VERSION ""

NS_ :

BS_ :

BU_: VCU MCU BJM1 BJM2 BJM3

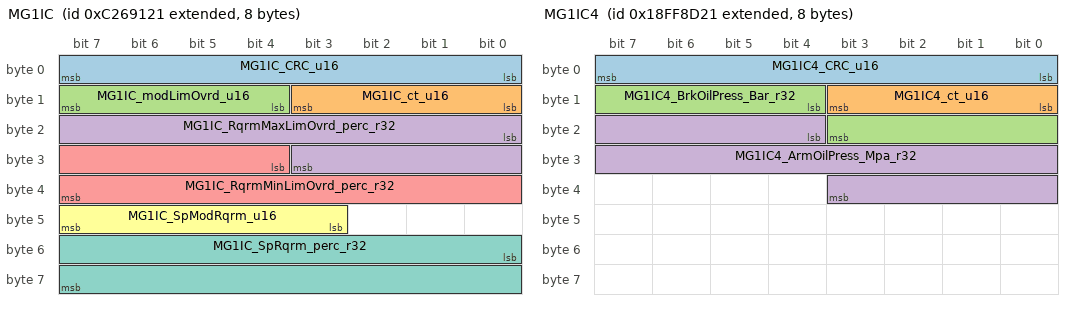
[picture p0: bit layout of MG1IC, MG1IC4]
BO_ 2351337761 MG1IC: 8 Vector__XXX
 SG_ MG1IC_CRC_u16 : 0|8@1- (1,0) [0|255] "count" MCU
 SG_ MG1IC_ct_u16 : 8|4@1- (1,0) [0|15] "" MCU
 SG_ MG1IC_modLimOvrd_u16 : 12|4@1- (1,0) [0|15] "" MCU
 SG_ MG1IC_RqrmMaxLimOvrd_perc_r32 : 16|12@1- (0.0625,-125) [-125|125.9375] "%" MCU
 SG_ MG1IC_RqrmMinLimOvrd_perc_r32 : 28|12@1- (0.0625,-125) [-125|125.9375] "%" MCU
 SG_ MG1IC_SpModRqrm_u16 : 43|5@1- (1,0) [0|31] "" MCU
 SG_ MG1IC_SpRqrm_perc_r32 : 48|16@1- (0.00390625,-125) [-125|125.99609375] "%" MCU

BO_ 2566884641 MG1IC4: 8 Vector__XXX
 SG_ MG1IC4_CRC_u16 : 0|8@1- (1,0) [0|255] "count" MCU
 SG_ MG1IC4_ct_u16 : 8|4@1- (1,0) [0|15] "" MCU
 SG_ MG1IC4_BrkOilPress_Bar_r32 : 12|8@1- (0.5,0) [0|125] "bar" MCU
 SG_ MG1IC4_ArmOilPress_Mpa_r32 : 20|16@1- (0.0009765625,0) [0|62.7490234375] "Mpa" MCU

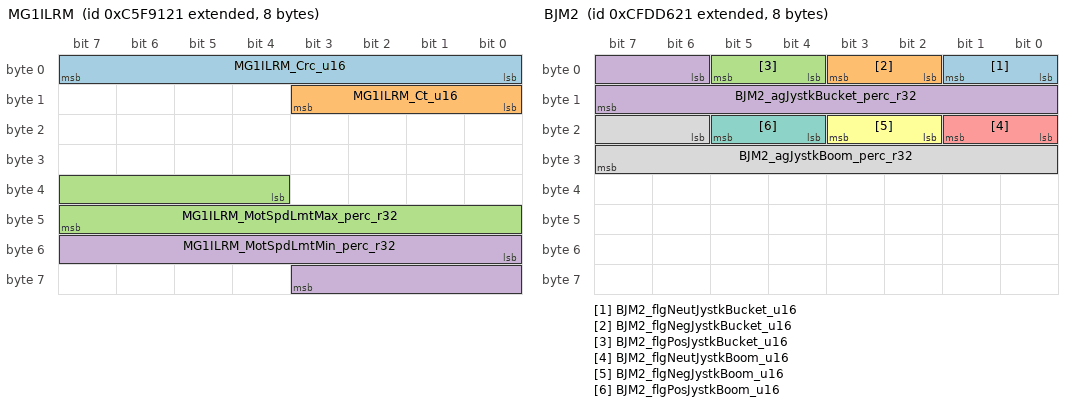
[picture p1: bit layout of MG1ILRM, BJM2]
BO_ 2355073313 MG1ILRM: 8 Vector__XXX
 SG_ MG1ILRM_Crc_u16 : 0|8@1- (1,0) [0|255] "count" MCU
 SG_ MG1ILRM_Ct_u16 : 8|4@1- (1,0) [0|15] "" MCU
 SG_ MG1ILRM_MotSpdLmtMax_perc_r32 : 36|12@1- (0,0) [-125|0] "%" MCU
 SG_ MG1ILRM_MotSpdLmtMin_perc_r32 : 48|12@1- (0,0) [-125|0] "%" MCU

BO_ 2365445665 BJM2: 8 Vector__XXX
 SG_ BJM2_flgNeutJystkBucket_u16 : 0|2@1- (1,0) [0|3] "" MCU
 SG_ BJM2_flgNegJystkBucket_u16 : 2|2@1- (1,0) [0|3] "" MCU
 SG_ BJM2_flgPosJystkBucket_u16 : 4|2@1- (1,0) [0|3] "" MCU
 SG_ BJM2_agJystkBucket_perc_r32 : 6|10@1- (0.1,0) [0|102] "%" MCU
 SG_ BJM2_flgNeutJystkBoom_u16 : 16|2@1- (1,0) [0|3] "" MCU
 SG_ BJM2_flgNegJystkBoom_u16 : 18|2@1- (1,0) [0|3] "" MCU
 SG_ BJM2_flgPosJystkBoom_u16 : 20|2@1- (1,0) [0|3] "" MCU
 SG_ BJM2_agJystkBoom_perc_r32 : 22|10@1- (0.1,0) [0|102] "%" MCU

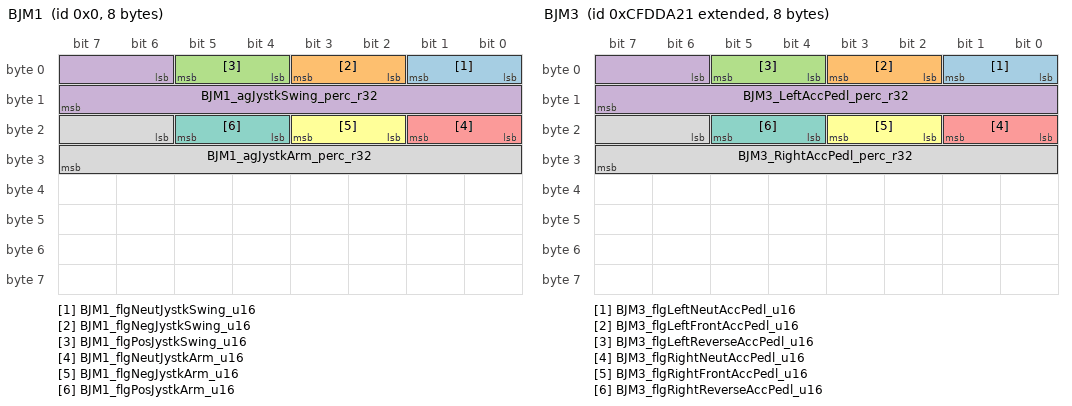
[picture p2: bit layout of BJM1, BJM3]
BO_ 0 BJM1: 8 Vector__XXX
 SG_ BJM1_flgNeutJystkSwing_u16 : 0|2@1- (1,0) [0|3] "" MCU
 SG_ BJM1_flgNegJystkSwing_u16 : 2|2@1- (1,0) [0|3] "" MCU
 SG_ BJM1_flgPosJystkSwing_u16 : 4|2@1- (1,0) [0|3] "" MCU
 SG_ BJM1_agJystkSwing_perc_r32 : 6|10@1- (0.1,0) [0|102] "%" MCU
 SG_ BJM1_flgNeutJystkArm_u16 : 16|2@1- (1,0) [0|3] "" MCU
 SG_ BJM1_flgNegJystkArm_u16 : 18|2@1- (1,0) [0|3] "" MCU
 SG_ BJM1_flgPosJystkArm_u16 : 20|2@1- (1,0) [0|3] "" MCU
 SG_ BJM1_agJystkArm_perc_r32 : 22|10@1- (0.1,0) [0|102] "%" MCU

BO_ 2365446689 BJM3: 8 Vector__XXX
 SG_ BJM3_flgLeftNeutAccPedl_u16 : 0|2@1- (1,0) [0|3] "" MCU
 SG_ BJM3_flgLeftFrontAccPedl_u16 : 2|2@1- (1,0) [0|3] "" MCU
 SG_ BJM3_flgLeftReverseAccPedl_u16 : 4|2@1- (1,0) [0|3] "" MCU
 SG_ BJM3_LeftAccPedl_perc_r32 : 6|10@1- (0.1,0) [0|102] "%" MCU
 SG_ BJM3_flgRightNeutAccPedl_u16 : 16|2@1- (1,0) [0|3] "" MCU
 SG_ BJM3_flgRightFrontAccPedl_u16 : 18|2@1- (1,0) [0|3] "" MCU
 SG_ BJM3_flgRightReverseAccPedl_u16 : 20|2@1- (1,0) [0|3] "" MCU
 SG_ BJM3_RightAccPedl_perc_r32 : 22|10@1- (0.1,0) [0|102] "%" MCU

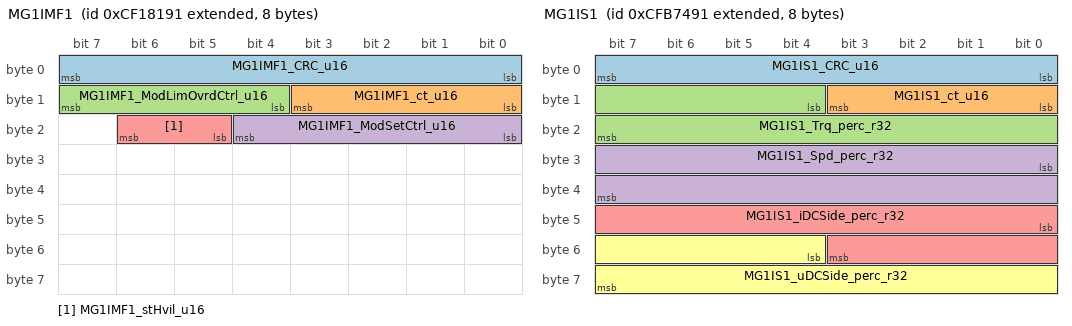
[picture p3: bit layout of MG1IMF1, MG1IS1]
BO_ 2364637585 MG1IMF1: 8 Vector__XXX
 SG_ MG1IMF1_CRC_u16 : 0|8@1- (1,0) [0|255] "count" VCU
 SG_ MG1IMF1_ct_u16 : 8|4@1- (1,0) [0|15] "" VCU
 SG_ MG1IMF1_ModLimOvrdCtrl_u16 : 12|4@1- (1,0) [0|15] "" VCU
 SG_ MG1IMF1_ModSetCtrl_u16 : 16|5@1- (1,0) [0|31] "" VCU
 SG_ MG1IMF1_stHvil_u16 : 21|2@1- (1,0) [0|3] "" VCU

BO_ 2365289617 MG1IS1: 8 Vector__XXX
 SG_ MG1IS1_CRC_u16 : 0|8@1- (1,0) [0|255] "count" VCU
 SG_ MG1IS1_ct_u16 : 8|4@1- (1,0) [0|15] "" VCU
 SG_ MG1IS1_Trq_perc_r32 : 12|12@1- (0.0625,-125) [-125|125.9375] "%" VCU
 SG_ MG1IS1_Spd_perc_r32 : 24|16@1- (0.00390625,-125) [-125|125.99609375] "%" VCU
 SG_ MG1IS1_iDCSide_perc_r32 : 40|12@1- (0.0625,-125) [-125|125.9375] "%" VCU
 SG_ MG1IS1_uDCSide_perc_r32 : 52|12@1- (0.0625,-125) [-125|125.9375] "%" VCU

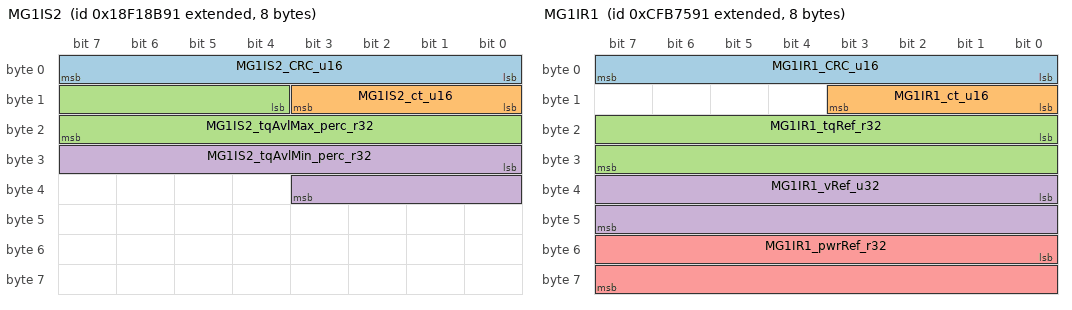
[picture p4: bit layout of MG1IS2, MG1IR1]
BO_ 2565966737 MG1IS2: 8 Vector__XXX
 SG_ MG1IS2_CRC_u16 : 0|8@1- (1,0) [0|255] "" VCU
 SG_ MG1IS2_ct_u16 : 8|4@1- (1,0) [0|15] "" VCU
 SG_ MG1IS2_tqAvlMax_perc_r32 : 12|12@1- (0.0625,-125) [-125|125.9375] "%" VCU
 SG_ MG1IS2_tqAvlMin_perc_r32 : 24|12@1- (0.0625,-125) [-125|125.9375] "%" VCU

BO_ 2365289873 MG1IR1: 8 Vector__XXX
 SG_ MG1IR1_CRC_u16 : 0|8@1- (1,0) [0|255] "count" VCU
 SG_ MG1IR1_ct_u16 : 8|4@1- (1,0) [0|15] "" VCU
 SG_ MG1IR1_tqRef_r32 : 16|16@1- (0.5,0) [0|32127.5] "Nm" VCU
 SG_ MG1IR1_vRef_u32 : 32|16@1- (4,0) [0|257020] "rpm" VCU
 SG_ MG1IR1_pwrRef_r32 : 48|16@1- (0.0625,0) [0|4015.9375] "kW" VCU

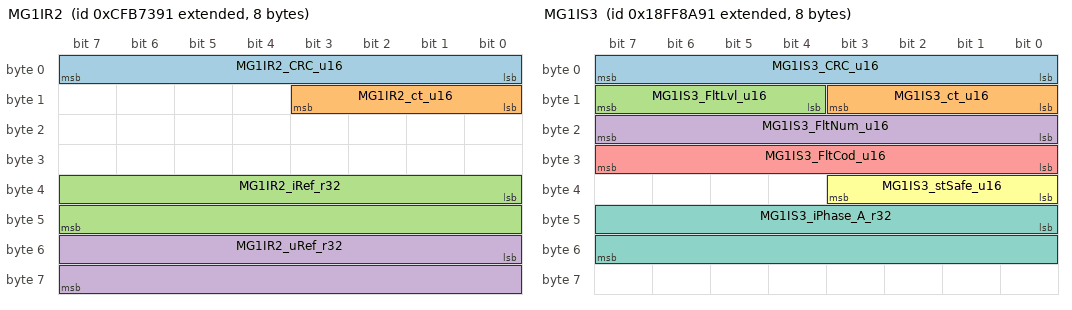
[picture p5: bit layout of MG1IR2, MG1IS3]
BO_ 2365289361 MG1IR2: 8 Vector__XXX
 SG_ MG1IR2_CRC_u16 : 0|8@1- (1,0) [0|255] "count" VCU
 SG_ MG1IR2_ct_u16 : 8|4@1- (1,0) [0|15] "" VCU
 SG_ MG1IR2_iRef_r32 : 32|16@1- (0.125,0) [0|8031.875] "A" VCU
 SG_ MG1IR2_uRef_r32 : 48|16@1- (0.125,0) [0|8031.875] "V" VCU

BO_ 2566615441 MG1IMT: 8 Vector__XXX
 SG_ MG1IMT_t1Mot_u16 : 0|8@1- (1,-40) [-40|210] "°C" VCU

BO_ 2566615697 MG1IT: 8 Vector__XXX
 SG_ MG1IT_t1Ivtr_u16 : 0|8@1- (1,-40) [-40|210] "°C" VCU

BO_ 2566883985 MG1IS3: 8 Vector__XXX
 SG_ MG1IS3_CRC_u16 : 0|8@1- (1,0) [0|255] "count" VCU
 SG_ MG1IS3_ct_u16 : 8|4@1- (1,0) [0|15] "" VCU
 SG_ MG1IS3_FltLvl_u16 : 12|4@1- (1,0) [0|15] "" VCU
 SG_ MG1IS3_FltNum_u16 : 16|8@1- (1,0) [0|255] "count" VCU
 SG_ MG1IS3_FltCod_u16 : 24|8@1- (1,0) [0|255] "" VCU
 SG_ MG1IS3_stSafe_u16 : 32|4@1- (1,0) [0|15] "" VCU
 SG_ MG1IS3_iPhase_A_r32 : 40|16@1- (0.1,0) [-3212.7|3212.8] "A" VCU

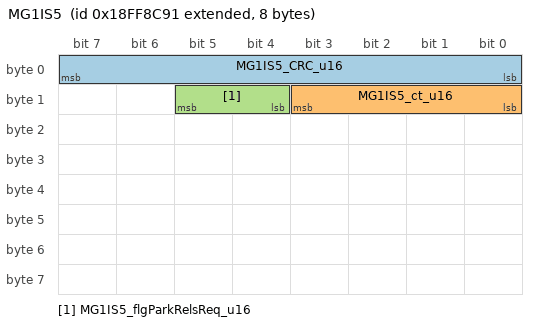
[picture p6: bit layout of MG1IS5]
BO_ 2566884497 MG1IS5: 8 Vector__XXX
 SG_ MG1IS5_CRC_u16 : 0|8@1- (1,0) [0|255] "count" VCU
 SG_ MG1IS5_ct_u16 : 8|4@1- (1,0) [0|15] "" VCU
 SG_ MG1IS5_flgParkRelsReq_u16 : 12|2@1- (1,0) [0|3] "" VCU

CM_ BO_ 2351337761 "Motor/Generator 1 Inverter Control";
CM_ SG_ 2351337761 MG1IC_CRC_u16 "CRC";
CM_ SG_ 2351337761 MG1IC_ct_u16 "Counter";
CM_ SG_ 2351337761 MG1IC_modLimOvrd_u16 "This parameter provides a way to temporarily override limits that are being received by the inverter in other messages.  It allows a specific type of limit to be transmitted at a high rate or at the same moment as the set point for synchronization purposes.
过载限制模式";
CM_ SG_ 2351337761 MG1IC_RqrmMaxLimOvrd_perc_r32 "The Maximum limit requested by this parameter depends on the value of SPN 10159 [Control Limits Request Override Mode].
过载限制模式最大百分比";
CM_ SG_ 2351337761 MG1IC_RqrmMinLimOvrd_perc_r32 "The Minimum limit requested by this parameter depends on the value of SPN 10159 [Control Limits Request Override Mode].
过载限制模式最小百分比";
CM_ SG_ 2351337761 MG1IC_SpModRqrm_u16 "Requests the modes for this instance of the inverter.  See SPN 10167 [Control Setpoint Mode] for the feedback to this request.
工作模式设置";
CM_ SG_ 2351337761 MG1IC_SpRqrm_perc_r32 "Requests the set point for this inverter.  The type of set point requested by this parameter depends on the value of SPN 10162 [Control Setpoint Mode Request] as follows:
对应工作模式的需求百分比";
CM_ BO_ 2566884641 "Motor/Generator 1 Inverter Control 4";
CM_ SG_ 2566884641 MG1IC4_CRC_u16 "CRC";
CM_ SG_ 2566884641 MG1IC4_ct_u16 "Counter";
CM_ SG_ 2566884641 MG1IC4_BrkOilPress_Bar_r32 "Brake oil pressure
松闸油压信号";
CM_ SG_ 2566884641 MG1IC4_ArmOilPress_Mpa_r32 "Boom cylinder rod pressure
动臂小腔油压";
CM_ BO_ 2355073313 "Motor/Generator 1 Inverter Limits Request Mechanical";
CM_ SG_ 2355073313 MG1ILRM_MotSpdLmtMax_perc_r32 "This is a request to the inverter to set a maximum speed limit for this device.
电机最高转速限制";
CM_ SG_ 2355073313 MG1ILRM_MotSpdLmtMin_perc_r32 "This is a request to the inverter to set a minimum speed limit for this device.
电机最低转速限制";
CM_ BO_ 2365445665 "Basic Joystick Message2";
CM_ SG_ 2365445665 BJM2_flgNeutJystkBucket_u16 "Bucket joystick median signal
铲斗手柄中位信号";
CM_ SG_ 2365445665 BJM2_flgNegJystkBucket_u16 "Bucket joystick negative signal
铲斗手柄负位信号";
CM_ SG_ 2365445665 BJM2_flgPosJystkBucket_u16 "Bucket joystick positive signal
铲斗手柄正位信号";
CM_ SG_ 2365445665 BJM2_agJystkBucket_perc_r32 "Bucket joystick joystick signal
铲斗手柄信号";
CM_ SG_ 2365445665 BJM2_flgNeutJystkBoom_u16 "Boom joystick median signal
动臂手柄中位信号";
CM_ SG_ 2365445665 BJM2_flgNegJystkBoom_u16 "Boom joystick negative signal
动臂手柄负位信号";
CM_ SG_ 2365445665 BJM2_flgPosJystkBoom_u16 "Boom joystick positive signal
动臂手柄正位信号";
CM_ SG_ 2365445665 BJM2_agJystkBoom_perc_r32 "Boom joystick signal
动臂手柄信号";
CM_ BO_ 0 "Basic Joystick Message 1";
CM_ SG_ 0 BJM1_flgNeutJystkSwing_u16 "Swing joystick median signal
回转手柄中位信号";
CM_ SG_ 0 BJM1_flgNegJystkSwing_u16 "Swing joystick negative signal
回转手柄负位信号";
CM_ SG_ 0 BJM1_flgPosJystkSwing_u16 "Swing joystick positive signal
回转手柄正位信号";
CM_ SG_ 0 BJM1_agJystkSwing_perc_r32 "Swing joystick joystick signal
回转手柄信号";
CM_ SG_ 0 BJM1_flgNeutJystkArm_u16 "Arm joystick median signal
斗杆手柄中位信号";
CM_ SG_ 0 BJM1_flgNegJystkArm_u16 "Arm lever joystick negative signal
斗杆手柄负位信号";
CM_ SG_ 0 BJM1_flgPosJystkArm_u16 "Arm lever joystick positive signal
斗杆手柄正位信号";
CM_ SG_ 0 BJM1_agJystkArm_perc_r32 "Arm  lever joystick signal
斗杆手柄信号";
CM_ BO_ 2365446689 "Basic Joystick Message3";
CM_ SG_ 2365446689 BJM3_flgLeftNeutAccPedl_u16 "Left accelerator pedal median signal
左行走踏板中位信号";
CM_ SG_ 2365446689 BJM3_flgLeftFrontAccPedl_u16 "Left accelerator pedal front signal
左行走踏板正位信号";
CM_ SG_ 2365446689 BJM3_flgLeftReverseAccPedl_u16 "Left accelerator pedal reverse signal
左行走踏板负位信号";
CM_ SG_ 2365446689 BJM3_LeftAccPedl_perc_r32 "Left accelerator pedal signal
左行走踏板信号";
CM_ SG_ 2365446689 BJM3_flgRightNeutAccPedl_u16 "Right accelerator pedal median signal
右行走踏板中位信号";
CM_ SG_ 2365446689 BJM3_flgRightFrontAccPedl_u16 "Right accelerator pedal front signal
右行走踏板正位信号";
CM_ SG_ 2365446689 BJM3_flgRightReverseAccPedl_u16 "Right accelerator pedal reverse signal
右行走踏板负位信号";
CM_ SG_ 2365446689 BJM3_RightAccPedl_perc_r32 "Right accelerator pedal signal
右行走踏板信号";
CM_ BO_ 2364637585 "Motor/Generator 1 Inverter Mode Feedback 1";
CM_ SG_ 2364637585 MG1IMF1_CRC_u16 "CRC";
CM_ SG_ 2364637585 MG1IMF1_ct_u16 "Counter";
CM_ SG_ 2364637585 MG1IMF1_ModLimOvrdCtrl_u16 "Inverter Control Limits Override Mode
当前的过载限制模式";
CM_ SG_ 2364637585 MG1IMF1_ModSetCtrl_u16 "Inverter Control Setpoint Mode
当前的工作模式";
CM_ SG_ 2364637585 MG1IMF1_stHvil_u16 "Inverter HVIL Status
当前的高压互锁状态";
CM_ BO_ 2365289617 "Motor/Generator 1 Inverter Status 1";
CM_ SG_ 2365289617 MG1IS1_CRC_u16 "CRC";
CM_ SG_ 2365289617 MG1IS1_ct_u16 "Counter";
CM_ SG_ 2365289617 MG1IS1_Trq_perc_r32 "The calculated Torque
当前的扭矩百分比";
CM_ SG_ 2365289617 MG1IS1_Spd_perc_r32 "The measured Speed
当前的速度百分比";
CM_ SG_ 2365289617 MG1IS1_iDCSide_perc_r32 "This is the DC side current of the inverter. Refer to SPN 10202 [Reference Current] to convert % to Amps. While motoring, the current is defined as positive.  For example, in a hybrid propulsion system, positive current flows from the HVES through ...This is the DC side current of the inverter. Refer to SPN 10202 [Reference Current] to convert % to Amps. While motoring, the current is defined as positive.  For example, in a hybrid propulsion system, positive current flows from the HVES through ...
当前的DC端电流百分比";
CM_ SG_ 2365289617 MG1IS1_uDCSide_perc_r32 "The measured or estimated DC side voltage. Refer to SPN 10203 [Reference Voltage] to convert % to Volts.
当前的DC端电压百分比";
CM_ BO_ 2565966737 "Motor/Generator 1 Inverter Status 2";
CM_ SG_ 2565966737 MG1IS2_CRC_u16 "CRC";
CM_ SG_ 2565966737 MG1IS2_ct_u16 "Counter";
CM_ SG_ 2565966737 MG1IS2_tqAvlMax_perc_r32 "This is an estimate of the maximum available motor torque including active deratings at the present motor speed.  This refers to the motor rotor output and excludes any gearbox that may be attached to the motor.   
当前的最大可用扭矩百分比";
CM_ SG_ 2565966737 MG1IS2_tqAvlMin_perc_r32 "This is an estimate of the minimum available motor torque including active deratings at the present motor speed.  This refers to the motor rotor output and excludes any gearbox that may be attached to the motor.  
当前的最小可用扭矩百分比";
CM_ BO_ 2365289873 "Motor/Generator 1 Inverter Reference 1";
CM_ SG_ 2365289873 MG1IR1_CRC_u16 "CRC";
CM_ SG_ 2365289873 MG1IR1_ct_u16 "Counter";
CM_ SG_ 2365289873 MG1IR1_tqRef_r32 "This value is used for converting torque in percent to units of Nm.

Value in Nm = (Percent Value)/(100%) * (Reference Torque)

For example, if this parameter has a value of 400 Nm and the percent value is equal to 75%, then the value in Nm will be found as follows:

Value in Nm = (75%)/(100%) * (400 Nm) = 300 Nm
参照扭矩，用于配合百分比值进行计算";
CM_ SG_ 2365289873 MG1IR1_vRef_u32 "This value is used for converting Speed in percent to units of rpm.

Value in rpm = (Percent Value)/(100%) * (Reference Speed)

For example, if this parameter has a value of 8192 rpm and the percent value is equal to 75%, then the value in rpm will be found as follows:

Value in rpm = (75%)/(100%) * (8192 rpm) = 6144 rpm
参照转速，用于配合百分比值进行计算";
CM_ SG_ 2365289873 MG1IR1_pwrRef_r32 "This value is used for converting power in percent to units of kW.  It is applicable to both mechanical and electrical power.

(Value in kW) = (Percent Value)/(100%) * (Reference Power)

For example, if this parameter has a value of 400 kW and the percent value is equal to 75%, then the value in kW will be found as follows:

Value in kW = (75%)/(100%) * (400 kW) = 300 kW
参照功率，用于配合百分比值进行计算";
CM_ BO_ 2365289361 "Motor/Generator 1 Inverter Reference 2";
CM_ SG_ 2365289361 MG1IR2_CRC_u16 "CRC";
CM_ SG_ 2365289361 MG1IR2_ct_u16 "Counter";
CM_ SG_ 2365289361 MG1IR2_iRef_r32 "This value is used for converting inverter current in percent to units of Amps (RMS or DC).

(Value in Amps) = (Percent Value)/(100%) * (Reference Current)

For example, if this parameter has a value of 200 A and the percent value is equal to 75%, then the value in Amps will be found as follows:

Value in Amps = (75%)/(100%) * (200 A) = 150 A
参照电流，用于百分比值进行计算";
CM_ SG_ 2365289361 MG1IR2_uRef_r32 "This value is used for converting inverter voltage in percent to units of Volts (RMS or DC).

(Value in Volts) = (Percent Value)/(100%) * (Reference Voltage)

For example, if this parameter has a value of 400 V and the percent value is equal to 75%, then the value in Volts will be found as follows:

Value in Volts = (75%)/(100%) * (400 V) = 300 V
参照电压，用于百分比值进行计算";
CM_ BO_ 2566615441 "Motor/Generator 1 Inverter Motor Temperature";
CM_ SG_ 2566615441 MG1IMT_t1Mot_u16 "The exact location of this temperature can be defined by the manufacturer.  It is intended to located somewhere on the motor.
电机温度";
CM_ BO_ 2566615697 "Motor/Generator 1 Inverter Temperature";
CM_ SG_ 2566615697 MG1IT_t1Ivtr_u16 "The exact location of this temperature can be defined by the manufacturer.  It is intended to be located somewhere on the inverter.
电机控制器温度";
CM_ BO_ 2566883985 "Motor/Generator 1 Inverter Status 3";
CM_ SG_ 2566883985 MG1IS3_CRC_u16 "CRC";
CM_ SG_ 2566883985 MG1IS3_ct_u16 "Counter";
CM_ SG_ 2566883985 MG1IS3_FltLvl_u16 "MCU fault level.Only report the heightest level fault
MCU 故障等级,值上报最高故障等级";
CM_ SG_ 2566883985 MG1IS3_FltNum_u16 "MCU fault numbers for current cycle
当前循环的故障数量";
CM_ SG_ 2566883985 MG1IS3_FltCod_u16 "MCU fault code for current cycle
当前循环的故障码";
CM_ SG_ 2566883985 MG1IS3_stSafe_u16 "MCU safe status
MCU的安全状态";
CM_ SG_ 2566883985 MG1IS3_iPhase_A_r32 "Phase current(RMS)
相电流";
CM_ BO_ 2566884497 "Motor/Generator 1 Inverter Status 5";
CM_ SG_ 2566884497 MG1IS5_CRC_u16 "CRC";
CM_ SG_ 2566884497 MG1IS5_ct_u16 "Counter";
CM_ SG_ 2566884497 MG1IS5_flgParkRelsReq_u16 "Parking brake release reuqire signal
逆变器松闸请求";

BA_DEF_ BO_ "GenMsgSendType" ENUM "cyclic","reserved","cyclicIfActive","reserved","reserved","reserved","reserved","reserved","noMsgSendType";
BA_DEF_ BO_ "VFrameFormat" ENUM "StandardCAN","ExtendedCAN","reserved","J1939PG";
BA_DEF_ BO_ "GenMsgCycleTime" INT 0 3600000;
BA_DEF_ "BusType" STRING;
BA_DEF_ "ProtocolType" STRING;

BA_DEF_DEF_ "GenMsgSendType" "cyclic";
BA_DEF_DEF_ "VFrameFormat" "StandardCAN";
BA_DEF_DEF_ "GenMsgCycleTime" 0;
BA_DEF_DEF_ "BusType" "CAN";
BA_DEF_DEF_ "ProtocolType" "CAN";

BA_ "GenMsgCycleTime" BO_ 2351337761 10;
BA_ "GenMsgCycleTime" BO_ 2566884641 10;
BA_ "VFrameFormat" BO_ 2355073313 3;
BA_ "GenMsgCycleTime" BO_ 2355073313 10;
BA_ "GenMsgCycleTime" BO_ 2365445665 10;
BA_ "GenMsgCycleTime" BO_ 0 10;
BA_ "GenMsgCycleTime" BO_ 2365446689 10;
BA_ "GenMsgCycleTime" BO_ 2364637585 100;
BA_ "GenMsgCycleTime" BO_ 2365289617 10;
BA_ "GenMsgCycleTime" BO_ 2565966737 100;
BA_ "GenMsgCycleTime" BO_ 2365289873 1000;
BA_ "GenMsgCycleTime" BO_ 2365289361 1000;
BA_ "GenMsgCycleTime" BO_ 2566615441 1000;
BA_ "GenMsgCycleTime" BO_ 2566615697 1000;
BA_ "GenMsgCycleTime" BO_ 2566883985 50;
BA_ "GenMsgCycleTime" BO_ 2566884497 10;

VAL_ 2351337761 MG1IC_modLimOvrd_u16 0 "NoLimit" 1 "TorqueLimitMode" 2 "SpeedLimitMode" 3 "DcSideVoltageLimitMode" 4 "DcSideCurrentLimitMode" 5 "DcSidePowerLimitMode" 6 "MechanicalPowerLimitMode" 14 "Error" 15 "NoRequest" ;
VAL_ 2351337761 MG1IC_SpModRqrm_u16 0 "PowerOn" 1 "SaeReserved" 2 "Standby" 5 "ManufacturerSpecificPassiveMode1" 6 "ManufacturerSpecificPassiveMode2" 7 "EnableTorqueControlMode" 8 "EnableSpeedControlMode" 9 "EnableDcSideVoltageMode" 10 "EnableDcSideCurrentMode" 11 "EnableDcPowerControlMode" 12 "EnableMechanicalPowerControlMode" 18 "ManufacturerSpecificActiveMode1" 19 "ManufacturerSpecificActiveMode2" 20 "InverterActiveDischargeModeEg" 21 "InverterPowerDownCommandMode" 28 "ManufacturerSpecificSpecialMode1" 29 "ManufacturerSpecificSpecialMode2" 31 "Don'tCare/takeNoAction" ;
VAL_ 2364637585 MG1IMF1_ModLimOvrdCtrl_u16 0 "OperatingLimitsAreNotOverridden" 1 "TorqueLimitsMode" 2 "SpeedLimitsMode" 3 "DcSideVoltageLimitsMode" 4 "DcSideCurrentLimitsMode" 5 "DcSidePowerLimitsMode" 6 "MechanicalPowerLimitsMode" 14 "Error" 15 "NotAvailable" ;
VAL_ 2364637585 MG1IMF1_ModSetCtrl_u16 0 "PoweredOn" 1 "WaitingForOperationalConditions" 2 "Standby" 5 "ManufacturerSpecificPassiveMode1" 6 "ManufacturerSpecificPassiveMode2" 7 "TorqueControlMode" 8 "SpeedControlMode" 9 "DcSideVoltageMode" 10 "DcSideCurrentMode" 11 "MechanicalPowerControlMode" 12 "DcPowerControlMode" 13 "DcSideVoltageControlMode" 18 "ManufacturerSpecificActiveMode1" 19 "ManufacturerSpecificActiveMode2" 20 "InverterActiveDischargeModeEg" 21 "InverterPowerDownCommand" 28 "ManufacturerSpecificSpecialMode1" 29 "ManufacturerSpecificSpecialMode2" 30 "Error" 31 "NotAvailable" ;
VAL_ 2364637585 MG1IMF1_stHvil_u16 0 "HVIL Closed" 1 "HVIL Open" 2 "Error" 3 "Not Available" ;
VAL_ 2566883985 MG1IS3_FltLvl_u16 0 "Normal(No fault)" 1 "1Level(Only report: no handling)" 2 "2Level(Derating: zero torque:recoverable fault)" 3 "3Level(Unrecoverable fault)" ;
